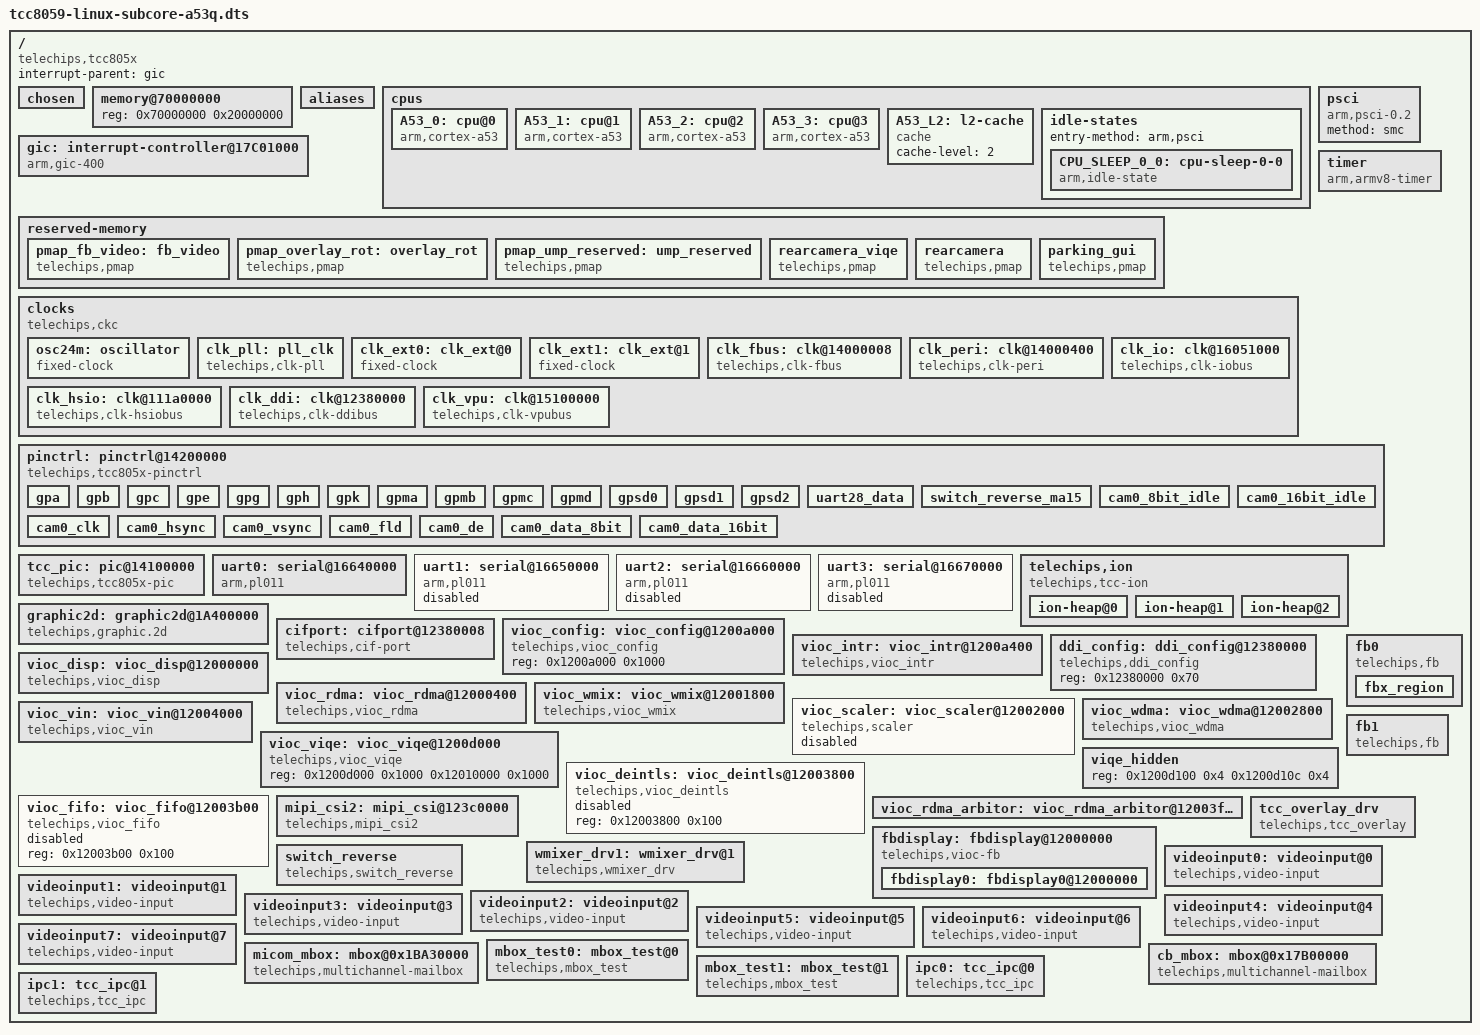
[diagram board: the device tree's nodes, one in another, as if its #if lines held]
// SPDX-License-Identifier: (GPL-2.0-or-later OR MIT)
/*
 * Copyright (C) Telechips Inc.
 * Device tree for Telechips TCC8059 Linux Subcore platform
 */

/dts-v1/;

#include <dt-bindings/interrupt-controller/arm-gic.h>
#include <dt-bindings/clock/telechips,tcc805x-clks.h>
#include <dt-bindings/reset/telechips,tcc805x-reset.h>
#include <dt-bindings/display/tcc805x-vioc.h>
#include <dt-bindings/power/telechips,boot-mode.h>
#include <dt-bindings/gpio/gpio.h>
#include <dt-bindings/mailbox/tcc805x_multi_mailbox/tcc_mbox_ch.h>
#include <dt-bindings/input/input.h>

#include "tcc-pmap-805x-subcore-a53q.dtsi"

/ {
	compatible = "telechips,tcc805x";
	interrupt-parent = <&gic>;
	#address-cells = <1>;
	#size-cells = <1>;

	chosen {
		bootargs = "vmalloc=480M cgroup_disable=memory console=ttyAMA0,115200n8 quiet";
		stdout-path = &uart0;
	};

	memory@70000000 {
		#address-cells = <1>;
		#size-cells = <1>;
		device_type = "memory";
		reg = <0x70000000 0x20000000>;
	};

	aliases {
		serial0 = &uart0;
		videoinput0 = &videoinput0;
		videoinput1 = &videoinput1;
		videoinput2 = &videoinput2;
		videoinput3 = &videoinput3;
		videoinput4 = &videoinput4;
		videoinput5 = &videoinput5;
		videoinput6 = &videoinput6;
		videoinput7 = &videoinput7;
		wmixer-drv1 = &wmixer_drv1;
//		tcc-overlay-drv1 = &tcc_overlay_drv1;
	};

	cpus {
		#address-cells = <1>;
		#size-cells = <0>;

		A53_0: cpu@0 {
			device_type = "cpu";
			compatible = "arm,cortex-a53";
			reg = <0x0>;
			enable-method = "psci";
			next-level-cache = <&A53_L2>;
			cpu-idle-states = <&CPU_SLEEP_0_0>;
			operating-points = <
				/* kHz    uV */
				/*1302000 1200000*/
				/*1226000 1150000*/
				/*1150000 1100000*/
				/*1074000 1050000*/
				/*998000 1100000*/
				/*908000 1100000*/
				950000 900000
			>;

			clocks = <&clk_fbus FBUS_CPU1>;
			clock-names = "cpu0";
			clock-latency = <300000>;
		};

		A53_1: cpu@1 {
			device_type = "cpu";
			compatible = "arm,cortex-a53";
			reg = <0x1>;
			enable-method = "psci";
			next-level-cache = <&A53_L2>;
		};

		A53_2: cpu@2 {
			device_type = "cpu";
			compatible = "arm,cortex-a53";
			reg = <0x2>;
			enable-method = "psci";
			next-level-cache = <&A53_L2>;
		};

		A53_3: cpu@3 {
			device_type = "cpu";
			compatible = "arm,cortex-a53";
			reg = <0x3>;
			enable-method = "psci";
			next-level-cache = <&A53_L2>;
		};

		A53_L2: l2-cache {
			compatible = "cache";
			cache-level = <2>;
		};

		idle-states {
			entry-method = "arm,psci";

			CPU_SLEEP_0_0: cpu-sleep-0-0 {
				compatible = "arm,idle-state";
				local-timer-stop;
				arm,psci-suspend-param = <0x0010000>;
				entry-latency-us = <250>;
				exit-latency-us = <500>;
				min-residency-us = <950>;
			};
		};
	};

	gic: interrupt-controller@17C01000 {
		compatible = "arm,gic-400", "telechips,tcc805x-pic";
		#interrupt-cells = <3>;
		#address-cells = <0>;
		interrupt-controller;
		reg = <0x17C01000 0x1000>,
		      <0x17C02000 0x1000>,
		      <0x17C04000 0x2000>,
		      <0x17C06000 0x2000>;
	};

	psci {
		compatible = "arm,psci-0.2";
		method = "smc";
	};

	timer {
		compatible = "arm,armv8-timer";
		interrupts = <GIC_PPI 13 (GIC_CPU_MASK_SIMPLE(4) | IRQ_TYPE_LEVEL_LOW)>,
			     <GIC_PPI 14 (GIC_CPU_MASK_SIMPLE(4) | IRQ_TYPE_LEVEL_LOW)>,
			     <GIC_PPI 11 (GIC_CPU_MASK_SIMPLE(4) | IRQ_TYPE_LEVEL_LOW)>,
			     <GIC_PPI 10 (GIC_CPU_MASK_SIMPLE(4) | IRQ_TYPE_LEVEL_LOW)>;
	};

	reserved-memory {
		#address-cells = <1>;
		#size-cells = <1>;
		ranges;

		/*-----------------------------------------------------------
		 * Secure Area 1 (CPU R/W, VPU X, GPU R/W, VIOC R)
		 *-----------------------------------------------------------
		 */
		pmap_fb_video: fb_video {
			compatible = "telechips,pmap";
			telechips,pmap-name = "fb_video";
			alloc-ranges = <RESERVED_MEM_BASE RESERVED_MEM_SIZE>;
			size = <PMAP_SIZE_FB_VIDEO>;
			no-map;
		};

		pmap_overlay_rot: overlay_rot {
			compatible = "telechips,pmap";
			telechips,pmap-name = "overlay_rot";
			alloc-ranges = <RESERVED_MEM_BASE RESERVED_MEM_SIZE>;
			size = <PMAP_SIZE_OVERLAY_ROT>; // Max-Displayed-Output(w*h*2) for device-rotation.
			no-map;
		};

		/*-----------------------------------------------------------
		 * Secure Area 4 (CPU X, VPU X, GPU R/W, VIOC R/W)
		 *-----------------------------------------------------------
		 */
		pmap_ump_reserved: ump_reserved {
			compatible = "telechips,pmap";
			telechips,pmap-name = "ump_reserved";
			alloc-ranges = <RESERVED_MEM_BASE RESERVED_MEM_SIZE>;
			size = <PMAP_SIZE_UMP_RESERVED>; // Max-Video-Resolution(Aligned_256KB(w*h*3/2)) * 12 + 1MB
		};

		/*-----------------------------------------------------------
		 * RearCamera Memory (synchronized with bootloader)
		 *-----------------------------------------------------------
		 */
		rearcamera_viqe: rearcamera_viqe {
			compatible = "telechips,pmap";
			telechips,pmap-name = "rearcamera_viqe";
			alloc-ranges = <REARCAMERA_MEM_BASE REARCAMERA_MEM_SIZE>;
			size = <PMAP_SIZE_REARCAMERA_VIQE>;
			no-map;
		};

		rearcamera: rearcamera {
			compatible = "telechips,pmap";
			telechips,pmap-name = "rearcamera";
			alloc-ranges = <REARCAMERA_MEM_BASE REARCAMERA_MEM_SIZE>;
			size = <PMAP_SIZE_REARCAMERA>;
			no-map;
		};

		parking_gui: parking_gui {
			compatible = "telechips,pmap";
			telechips,pmap-name = "parking_gui";
			alloc-ranges = <REARCAMERA_MEM_BASE REARCAMERA_MEM_SIZE>;
			size = <PMAP_SIZE_PARKING_GUI>;
			no-map;
		};
	};

	clocks {
		compatible = "telechips,ckc";

		osc24m: oscillator {
			compatible = "fixed-clock";
			#clock-cells = <0>;
			clock-frequency = <24000000>;
			clock-output-names = "osc24m";
		};

		clk_pll: pll_clk {
			compatible = "telechips,clk-pll";
			#clock-cells = <1>;
			clocks = <&osc24m>;
			clock-output-names = "pll0", "pll1", "pll2", "pll3",
					     "pll4";
		};

		clk_ext0: clk_ext@0 {
			compatible = "fixed-clock";
			#clock-cells = <0>;
			clock-frequency = <24000000>;
			clock-output-names = "clk_ext0";
		};

		clk_ext1: clk_ext@1 {
			compatible = "fixed-clock";
			#clock-cells = <0>;
			clock-frequency = <24000000>;
			clock-output-names = "clk_ext1";
		};

		clk_fbus: clk@14000008 {
			compatible = "telechips,clk-fbus";
			#clock-cells = <1>;
			clock-indices =
				<FBUS_CPU0>, <FBUS_CPU1>, <FBUS_CBUS>, <FBUS_CMBUS>,
				<FBUS_HSIO>, <FBUS_SMU>, <FBUS_GPU>, <FBUS_DDI>,
				<FBUS_G2D>, <FBUS_IO>, <FBUS_HSM>, <FBUS_PCIe0>,
				<FBUS_PCIe1>, <FBUS_VBUS>, <FBUS_CODA>, <FBUS_CHEVCDEC>,
				<FBUS_BHEVCDEC>, <FBUS_CHEVCENC>, <FBUS_BHEVCENC>, <FBUS_MEM>,
				<FBUS_MEM_SUB>, <FBUS_MEM_PHY_USER>,
				<FBUS_MEM_PHY_PERI>;
			clock-output-names =
				"fbus_cpu0", "fbus_cpu1", "fbus_cbus", "fbus_cmbus",
				"fbus_hsio", "fbus_smu", "fbus_gpu", "fbus_ddi",
				"fbus_g2d", "fbus_io", "fbus_hsm", "fbus_pcie0",
				"fbus_pcie1", "fbus_vbus", "fbus_coda", "fbus_chevcdec",
				"fbus_bhevcdec", "fbus_chevcenc", "fbus_bhevcenc", "fbus_mem",
				"fbus_mem_sub", "fbus_mem_phy_user",
				"fbus_mem_phy_peri";
			telechips,clock-flags =
				<0>,    /* FBUS_CPU0 */
				<CLK_IGNORE_UNUSED>,    /* FBUS_CPU1 */
				<(CLK_SET_RATE_GATE | CLK_IGNORE_UNUSED)>,    /* FBUS_CBUS */
				<(CLK_SET_RATE_GATE | CLK_IGNORE_UNUSED)>,    /* FBUS_CMBUS */
				<(CLK_SET_RATE_GATE | CLK_IGNORE_UNUSED)>,    /* FBUS_HSIO */
				<(CLK_SET_RATE_GATE | CLK_IGNORE_UNUSED)>,    /* FBUS_SMU */
				<(CLK_SET_RATE_GATE | CLK_IGNORE_UNUSED)>,   /* FBUS_GPU */
				<(CLK_SET_RATE_GATE | CLK_IGNORE_UNUSED)>,    /* FBUS_DDI */
				<(CLK_SET_RATE_GATE | CLK_IGNORE_UNUSED)>,    /* FBUS_G2D */
				<(CLK_SET_RATE_GATE | CLK_IS_CRITICAL)>,    /* FBUS_IO */
				<(CLK_SET_RATE_GATE | CLK_IGNORE_UNUSED)>,    /* FBUS_HSM */
				<(CLK_SET_RATE_GATE | CLK_IGNORE_UNUSED)>,    /* FBUS_PCIe0 */
				<(CLK_SET_RATE_GATE | CLK_IGNORE_UNUSED)>,    /* FBUS_PCIe1 */
				<(CLK_SET_RATE_GATE | CLK_IGNORE_UNUSED)>,    /* FBUS_VBUS */
				<(CLK_SET_RATE_GATE | CLK_IGNORE_UNUSED)>,    /* FBUS_CODA */
				<(CLK_SET_RATE_GATE | CLK_IGNORE_UNUSED)>,    /* FBUS_CHEVCDEC */
				<(CLK_SET_RATE_GATE | CLK_IGNORE_UNUSED)>,    /* FBUS_BHEVCDEC */
				<(CLK_SET_RATE_GATE | CLK_IGNORE_UNUSED)>,    /* FBUS_CHEVCENC */
				<(CLK_SET_RATE_GATE | CLK_IGNORE_UNUSED)>,    /* FBUS_BHEVCENC */
				<(CLK_SET_RATE_GATE | CLK_IGNORE_UNUSED)>,    /* FBUS_MEM */
				<(CLK_SET_RATE_GATE | CLK_IGNORE_UNUSED)>,    /* FBUS_MEM_SUB */
				<(CLK_SET_RATE_GATE | CLK_IGNORE_UNUSED)>,    /* FBUS_MEM_PHY_USER */
				<(CLK_SET_RATE_GATE | CLK_IGNORE_UNUSED)>;    /* FBUS_MEM_PHY_PERI */
		};

		clk_peri: clk@14000400 {
			compatible = "telechips,clk-peri";
			#clock-cells = <1>;
			clock-indices =
				<PERI_TCX>, <PERI_TCT>, <PERI_TCZ>,
				<PERI_LCDTIMER>, <PERI_LCD0>, <PERI_LCD1>,
				<PERI_LCD2>, <PERI_CPUINTERFACE0>,
				<PERI_CPUINTERFACE1>, <PERI_LCD3>, <PERI_GMAC>,
				<PERI_GMAC_PTP>, <PERI_PCIE0_AUX>,
				<PERI_PCIE0_REF_EXT>, <PERI_PCIE0_PHY_CR_CLK>,
				<PERI_PCIE1_AUX>, <PERI_PCIE1_REF_EXT>,
				<PERI_PCIE1_PHY_CR_CLK>, <PERI_RMT>, <PERI_GPSB3>,
				<PERI_SDMMC1>, <PERI_SDMMC2>, <PERI_CEC1_CORE>,
				<PERI_MDAI0>, <PERI_MFLT0_DAI>, <PERI_MSPDIF0>,
				<PERI_SRCH0_CORE>, <PERI_SRCH0_FILTER>,
				<PERI_SRCH0_SPDIF>, <PERI_PDM>, <PERI_CEC1_SFR>,
				<PERI_TSADC>, <PERI_I2C0>, <PERI_I2C1>, <PERI_I2C2>,
				<PERI_I2C3>, <PERI_UART0>, <PERI_UART1>,
				<PERI_UART2>, <PERI_UART3>, <PERI_MDAI1>,
				<PERI_MFLT1_DAI>, <PERI_MSPDIF1>, <PERI_MDAI2>,
				<PERI_GPSB0>, <PERI_GPSB1>, <PERI_GPSB2>,
				<PERI_GPSBMS0>, <PERI_GPSBMS1>, <PERI_GPSBMS2>,
				<PERI_UART4>, <PERI_AUX0_INPUT>,
				<PERI_AUX1_INPUT>, <PERI_MFLT2_DAI>,
				<PERI_AUX0_OUTPUT>, <PERI_AUX1_OUTPUT>,
				<PERI_MSPDIF2>, <PERI_IC_TC>, <PERI_SRCH1_CORE>,
				<PERI_SRCH1_FILTER>, <PERI_SRCH1_SPDIF>,
				<PERI_SRCH2_CORE>, <PERI_SRCH2_FILTER>,
				<PERI_SRCH2_SPDIF>, <PERI_SRCH3_CORE>,
				<PERI_SRCH3_FILTER>, <PERI_SRCH3_SPDIF>,
				<PERI_UART5>, <PERI_UART6>, <PERI_UART7>,
				<PERI_UART8>, <PERI_MDAI3>, <PERI_MFLT3_DAI>,
				<PERI_MSPDIF3>, <PERI_TSRX0>, <PERI_TSRX1>,
				<PERI_TSRX2>, <PERI_TSRX3>, <PERI_TSRX4>,
				<PERI_TSRX5>, <PERI_TSRX6>, <PERI_TSRX7>,
				<PERI_TSRX8>, <PERI_CB_WDT>, <PERI_OUT0>,
				<PERI_OUT1>, <PERI_OUT2>, <PERI_OUT3>, <PERI_OUT4>,
				<PERI_OUT5>, <PERI_HSMB>;

				clock-output-names =
				"peri_tcx", "peri_tct", "peri_tcz",
				"peri_lcdtimer", "peri_lcd0", "peri_lcd1",
				"peri_lcd2", "peri_cpuinterface0",
				"peri_cpuinterface1", "peri_lcd3", "peri_gmac",
				"peri_gmac_ptp", "peri_pcie0_aux",
				"peri_pcie0_ref_ext", "peri_pcie0_phy_cr_clk",
				"peri_pcie1_aux", "peri_pcie1_ref_ext",
				"peri_pcie1_phy_cr_clk", "peri_rmt", "peri_gpsb3",
				"peri_sdmmc1", "peri_sdmmc2", "peri_cec1_core",
				"peri_mdai0", "peri_mflt0_dai", "peri_mspdif0",
				"peri_srch0_core", "peri_srch0_filter",
				"peri_srch0_spdif", "peri_pdm", "peri_cec1_sfr",
				"peri_tsadc", "peri_i2c0", "peri_i2c1", "peri_i2c2",
				"peri_i2c3", "peri_uart0", "peri_uart1",
				"peri_uart2", "peri_uart3", "peri_mdai1",
				"peri_mflt1_dai", "peri_mspdif1", "peri_mdai2",
				"peri_gpsb0", "peri_gpsb1", "peri_gpsb2",
				"peri_gpsbms0", "peri_gpsbms1", "peri_gpsbms2",
				"peri_uart4", "peri_aux0_input",
				"peri_aux1_input", "peri_mflt2_dai",
				"peri_aux0_output", "peri_aux1_output",
				"peri_mspdif2", "peri_ic_tc", "peri_srch1_core",
				"peri_srch1_filter", "peri_srch1_spdif",
				"peri_srch2_core", "peri_srch2_filter",
				"peri_srch2_spdif", "peri_srch3_core",
				"peri_srch3_filter", "peri_srch3_spdif",
				"peri_uart5", "peri_uart6", "peri_uart7",
				"peri_uart8", "peri_mdai3", "peri_mflt3_dai",
				"peri_mspdif3", "peri_tsrx0", "peri_tsrx1",
				"peri_tsrx2", "peri_tsrx3", "peri_tsrx4",
				"peri_tsrx5", "peri_tsrx6", "peri_tsrx7",
				"peri_tsrx8", "peri_cb_wdt", "peri_out0",
				"peri_out1", "peri_out2", "peri_out3", "peri_out4",
				"peri_out5", "peri_hsmb";
			telechips,clock-flags =
				<CLK_IGNORE_UNUSED>,    /* PERI_TCX */
				<CLK_IGNORE_UNUSED>,    /* PERI_TCT */
				<CLK_IGNORE_UNUSED>,    /* PERI_TCZ */
				<CLK_IGNORE_UNUSED>,    /* PERI_LCDTIMER */
				<CLK_IGNORE_UNUSED>,    /* PERI_LCD0 */
				<CLK_IGNORE_UNUSED>,    /* PERI_LCD1 */
				<CLK_IGNORE_UNUSED>,    /* PERI_LCD2 */
				<CLK_IGNORE_UNUSED>,    /* PERI_CPUINTERFACE0 */
				<CLK_IGNORE_UNUSED>,    /* PERI_CPUINTERFACE1 */
				<CLK_IGNORE_UNUSED>,    /* PERI_LCD3 */
				<CLK_IGNORE_UNUSED>,    /* PERI_GMAC */
				<CLK_IGNORE_UNUSED>,    /* PERI_GMAC_PTP */
				<CLK_IGNORE_UNUSED>,    /* PERI_PCIE0_AUX */
				<CLK_IGNORE_UNUSED>,    /* PERI_PCIE0_REF_EXT */
				<CLK_IGNORE_UNUSED>,    /* PERI_PCIE0_PHY_CR_CLK */
				<CLK_IGNORE_UNUSED>,    /* PERI_PCIE1_AUX */
				<CLK_IGNORE_UNUSED>,    /* PERI_PCIE1_REF_EXT */
				<CLK_IGNORE_UNUSED>,    /* PERI_PCIE1_PHY_CR_CLK */
				<CLK_IGNORE_UNUSED>,    /* PERI_RMT */
				<CLK_IGNORE_UNUSED>,    /* PERI_GPSB3 */
				<CLK_IGNORE_UNUSED>,    /* PERI_SDMMC1 */
				<CLK_IGNORE_UNUSED>,    /* PERI_SDMMC2 */
				<CLK_IGNORE_UNUSED>,    /* PERI_CEC1_CORE */
				<CLK_IGNORE_UNUSED>,    /* PERI_MDAI0 */
				<CLK_IGNORE_UNUSED>,    /* PERI_MFLT0_DAI */
				<CLK_IGNORE_UNUSED>,    /* PERI_MSPDIF0 */
				<CLK_IGNORE_UNUSED>,    /* PERI_SRCH0_CORE */
				<CLK_IGNORE_UNUSED>,    /* PERI_SRCH0_FILTER */
				<CLK_IGNORE_UNUSED>,    /* PERI_SRCH0_SPDIF */
				<CLK_IGNORE_UNUSED>,    /* PERI_PDM */
				<CLK_IGNORE_UNUSED>,    /* PERI_CEC1_SFR */
				<CLK_IGNORE_UNUSED>,    /* PERI_TSADC */
				<CLK_IGNORE_UNUSED>,    /* PERI_I2C0 */
				<CLK_IGNORE_UNUSED>,    /* PERI_I2C1 */
				<CLK_IGNORE_UNUSED>,    /* PERI_I2C2 */
				<CLK_IGNORE_UNUSED>,    /* PERI_I2C3 */
				<CLK_IGNORE_UNUSED>,    /* PERI_UART0 */
				<CLK_IGNORE_UNUSED>,    /* PERI_UART1 */
				<CLK_IGNORE_UNUSED>,    /* PERI_UART2 */
				<CLK_IGNORE_UNUSED>,    /* PERI_UART3 */
				<CLK_IGNORE_UNUSED>,    /* PERI_MDAI1 */
				<CLK_IGNORE_UNUSED>,    /* PERI_MFLT1_DAI */
				<CLK_IGNORE_UNUSED>,    /* PERI_MSPDIF1 */
				<CLK_IGNORE_UNUSED>,    /* PERI_MDAI2 */
				<CLK_IGNORE_UNUSED>,    /* PERI_GPSB0 */
				<CLK_IGNORE_UNUSED>,    /* PERI_GPSB1 */
				<CLK_IGNORE_UNUSED>,    /* PERI_GPSB2 */
				<CLK_IGNORE_UNUSED>,    /* PERI_GPSBMS0 */
				<CLK_IGNORE_UNUSED>,    /* PERI_GPSBMS1 */
				<CLK_IGNORE_UNUSED>,    /* PERI_GPSBMS2 */
				<CLK_IGNORE_UNUSED>,    /* PERI_UART4 */
				<CLK_IGNORE_UNUSED>,    /* PERI_AUX0_INPUT */
				<CLK_IGNORE_UNUSED>,    /* PERI_AUX1_INPUT */
				<CLK_IGNORE_UNUSED>,    /* PERI_MFLT2_DAI */
				<CLK_IGNORE_UNUSED>,    /* PERI_AUX0_OUTPUT */
				<CLK_IGNORE_UNUSED>,    /* PERI_AUX1_OUTPUT */
				<CLK_IGNORE_UNUSED>,    /* PERI_MSPDIF2 */
				<CLK_IGNORE_UNUSED>,    /* PERI_IC_TC */
				<CLK_IGNORE_UNUSED>,    /* PERI_SRCH1_CORE */
				<CLK_IGNORE_UNUSED>,    /* PERI_SRCH1_FILTER */
				<CLK_IGNORE_UNUSED>,    /* PERI_SRCH1_SPDIF */
				<CLK_IGNORE_UNUSED>,    /* PERI_SRCH2_CORE */
				<CLK_IGNORE_UNUSED>,    /* PERI_SRCH2_FILTER */
				<CLK_IGNORE_UNUSED>,    /* PERI_SRCH2_SPDIF */
				<CLK_IGNORE_UNUSED>,    /* PERI_SRCH3_CORE */
				<CLK_IGNORE_UNUSED>,    /* PERI_SRCH3_FILTER */
				<CLK_IGNORE_UNUSED>,    /* PERI_SRCH3_SPDIF */
				<CLK_IGNORE_UNUSED>,    /* PERI_UART5 */
				<CLK_IGNORE_UNUSED>,    /* PERI_UART6 */
				<CLK_IGNORE_UNUSED>,    /* PERI_UART7 */
				<CLK_IGNORE_UNUSED>,    /* PERI_UART8 */
				<CLK_IGNORE_UNUSED>,    /* PERI_MDAI3 */
				<CLK_IGNORE_UNUSED>,    /* PERI_MFLT3_DAI */
				<CLK_IGNORE_UNUSED>,    /* PERI_MSPDIF3 */
				<CLK_IGNORE_UNUSED>,    /* PERI_TSRX0 */
				<CLK_IGNORE_UNUSED>,    /* PERI_TSRX1 */
				<CLK_IGNORE_UNUSED>,    /* PERI_TSRX2 */
				<CLK_IGNORE_UNUSED>,    /* PERI_TSRX3 */
				<CLK_IGNORE_UNUSED>,    /* PERI_TSRX4 */
				<CLK_IGNORE_UNUSED>,    /* PERI_TSRX5 */
				<CLK_IGNORE_UNUSED>,    /* PERI_TSRX6 */
				<CLK_IGNORE_UNUSED>,    /* PERI_TSRX7 */
				<CLK_IGNORE_UNUSED>,    /* PERI_TSRX8 */
				<CLK_IGNORE_UNUSED>,    /* PERI_CB_WDT */
				<CLK_IGNORE_UNUSED>,    /* PERI_OUT0 */
				<CLK_IGNORE_UNUSED>,    /* PERI_OUT1 */
				<CLK_IGNORE_UNUSED>,    /* PERI_OUT2 */
				<CLK_IGNORE_UNUSED>,    /* PERI_OUT3 */
				<CLK_IGNORE_UNUSED>,    /* PERI_OUT4 */
				<CLK_IGNORE_UNUSED>,    /* PERI_OUT5 */
				<CLK_IGNORE_UNUSED>;    /* PERI_HSMB */
		};

		clk_io: clk@16051000 {
			compatible = "telechips,clk-iobus";
			#clock-cells = <1>;
			clocks = <&clk_fbus FBUS_IO>;
			clock-indices =
				<IOBUS_IC_TC>, <IOBUS_GPSB6>, <IOBUS_PL080>,
                                <IOBUS_ASRC>, <IOBUS_DMA0>, <IOBUS_DMA1>,
                                <IOBUS_DMA2>, <IOBUS_DMA>, <IOBUS_PWM>,
                                <IOBUS_I2C_S2>, <IOBUS_REMOCON>, <IOBUS_PRT>,
                                <IOBUS_ADMA0>, <IOBUS_DAI0>, <IOBUS_SPDIF0>,
                                <IOBUS_AUDIO0>, <IOBUS_ADMA3>, <IOBUS_DAI3>,
                                <IOBUS_SPDIF3>, <IOBUS_AUDIO3>, <IOBUS_I2C_M0>,
                                <IOBUS_I2C_M1>, <IOBUS_I2C_M2>, <IOBUS_I2C_M3>,
                                <IOBUS_I2C_S0>, <IOBUS_I2C_S1>, <IOBUS_I2C0>,
                                <IOBUS_I2C1>, <IOBUS_GPSB_2>, <IOBUS_GPSB0>,
                                <IOBUS_GPSB1>, <IOBUS_GPSB2>, <IOBUS_GPSB3>,
                                <IOBUS_GPSB4>, <IOBUS_GPSB5>, <IOBUS_GPSB>,
                                <IOBUS_I2C_S3>, <IOBUS_I2C_M4>, <IOBUS_I2C_M5>,
                                <IOBUS_I2C_M6>, <IOBUS_I2C_M7>, <IOBUS_UART0>,
                                <IOBUS_UART1>, <IOBUS_UART2>, <IOBUS_UART3>,
                                <IOBUS_UART4>, <IOBUS_UART5>, <IOBUS_UART6>,
                                <IOBUS_UART7>, <IOBUS_UART8>, <IOBUS_SMARTCARD4>,
                                <IOBUS_UDMA0>, <IOBUS_UDMA1>, <IOBUS_UDMA2>,
                                <IOBUS_UDMA3>, <IOBUS_UART_SMARTCARD0>,
                                <IOBUS_UART_SMARTCARD1>, <IOBUS_UDMA4>, <IOBUS_UDMA5>,
                                <IOBUS_UDMA6>, <IOBUS_UDMA7>, <IOBUS_UDMA8>,
                                <IOBUS_ADMA1>, <IOBUS_DAI1>, <IOBUS_SPDIF1>,
                                <IOBUS_AUDIO1>, <IOBUS_ADMA2>, <IOBUS_DAI2>,
                                <IOBUS_SPDIF2>, <IOBUS_AUDIO2>, <IOBUS_ADMA4>,
                                <IOBUS_DAI4>, <IOBUS_SPDIF4>, <IOBUS_AUDIO4>,
                                <IOBUS_ADMA5>, <IOBUS_DAI5>, <IOBUS_SPDIF5>,
                                <IOBUS_AUDIO5>, <IOBUS_ADMA6>, <IOBUS_DAI6>,
                                <IOBUS_SPDIF6>, <IOBUS_AUDIO6>, <IOBUS_ADMA7>,
                                <IOBUS_DAI7>, <IOBUS_AUDIO7>, <IOBUS_GDMA1>,
                                <IOBUS_SDMMC1>, <IOBUS_SDMMC2>, <IOBUS_SDMMC>,
                                <IOBUS_SMC>, <IOBUS_NFC>, <IOBUS_EDICFG>,
                                <IOBUS_EDI>, <IOBUS_RTC>;
			clock-output-names =
				"iobus_ic_tc", "iobus_gpsb6", "iobus_pl080",
                                "iobus_asrc", "iobus_dma0", "iobus_dma1",
                                "iobus_dma2", "iobus_dma", "iobus_pwm",
                                "iobus_i2c_s2", "iobus_remocon", "iobus_prt",
                                "iobus_adma0", "iobus_dai0", "iobus_spdif0",
                                "iobus_audio0", "iobus_adma3", "iobus_dai3",
                                "iobus_spdif3", "iobus_audio3", "iobus_i2c_m0",
                                "iobus_i2c_m1", "iobus_i2c_m2", "iobus_i2c_m3",
                                "iobus_i2c_s0", "iobus_i2c_s1", "iobus_i2c0",
                                "iobus_i2c1", "iobus_gpsb_2", "iobus_gpsb0",
                                "iobus_gpsb1", "iobus_gpsb2", "iobus_gpsb3",
                                "iobus_gpsb4", "iobus_gpsb5", "iobus_gpsb",
                                "iobus_i2c_s3", "iobus_i2c_m4", "iobus_i2c_m5",
                                "iobus_i2c_m6", "iobus_i2c_m7", "iobus_uart0",
                                "iobus_uart1", "iobus_uart2", "iobus_uart3",
                                "iobus_uart4", "iobus_uart5", "iobus_uart6",
                                "iobus_uart7", "iobus_uart8", "iobus_smartcard4",
                                "iobus_udma0", "iobus_udma1", "iobus_udma2",
                                "iobus_udma3", "iobus_uart_smartcard0",
                                "iobus_uart_smartcard1", "iobus_udma4", "iobus_udma5",
                                "iobus_udma6", "iobus_udma7", "iobus_udma8",
                                "iobus_adma1", "iobus_dai1", "iobus_spdif1",
                                "iobus_audio1", "iobus_adma2", "iobus_dai2",
                                "iobus_spdif2", "iobus_audio2", "iobus_adma4",
                                "iobus_dai4", "iobus_spdif4", "iobus_audio4",
                                "iobus_adma5", "iobus_dai5", "iobus_spdif5",
                                "iobus_audio5", "iobus_adma6", "iobus_dai6",
                                "iobus_spdif6", "iobus_audio6", "iobus_adma7",
                                "iobus_dai7", "iobus_audio7", "iobus_gdma1",
                                "iobus_sdmmc1", "iobus_sdmmc2", "iobus_sdmmc",
                                "iobus_smc", "iobus_nfc", "iobus_edicfg",
                                "iobus_edi", "iobus_rtc";
			telechips,clock-flags =
				<CLK_IGNORE_UNUSED>,    /* IOBUS_IC_TC */
                                <CLK_IGNORE_UNUSED>,    /* IOBUS_GPSB6 */
                                <CLK_IGNORE_UNUSED>,    /* IOBUS_PL080 */
                                <CLK_IGNORE_UNUSED>,    /* IOBUS_ASRC */
                                <CLK_IGNORE_UNUSED>,    /* IOBUS_DMA0 */
                                <CLK_IGNORE_UNUSED>,    /* IOBUS_DMA1 */
                                <CLK_IGNORE_UNUSED>,    /* IOBUS_DMA2 */
                                <CLK_IGNORE_UNUSED>,    /* IOBUS_DMA */
                                <CLK_IGNORE_UNUSED>,    /* IOBUS_PWM */
                                <CLK_IGNORE_UNUSED>,    /* IOBUS_I2C_S2 */
                                <CLK_IGNORE_UNUSED>,    /* IOBUS_REMOCON */
                                <CLK_IGNORE_UNUSED>,    /* IOBUS_PRT */
                                <CLK_IGNORE_UNUSED>,    /* IOBUS_ADMA0 */
                                <CLK_IGNORE_UNUSED>,    /* IOBUS_DAI0 */
                                <CLK_IGNORE_UNUSED>,    /* IOBUS_SPDIF0 */
                                <CLK_IGNORE_UNUSED>,    /* IOBUS_AUDIO0 */
                                <CLK_IGNORE_UNUSED>,    /* IOBUS_ADMA3 */
                                <CLK_IGNORE_UNUSED>,    /* IOBUS_DAI3 */
                                <CLK_IGNORE_UNUSED>,    /* IOBUS_SPDIF3 */
                                <CLK_IGNORE_UNUSED>,    /* IOBUS_AUDIO3 */
                                <CLK_IGNORE_UNUSED>,    /* IOBUS_I2C_M0 */
                                <CLK_IGNORE_UNUSED>,    /* IOBUS_I2C_M1 */
                                <CLK_IGNORE_UNUSED>,    /* IOBUS_I2C_M2 */
                                <CLK_IGNORE_UNUSED>,    /* IOBUS_I2C_M3 */
                                <CLK_IGNORE_UNUSED>,    /* IOBUS_I2C_S0 */
                                <CLK_IGNORE_UNUSED>,    /* IOBUS_I2C_S1 */
                                <CLK_IGNORE_UNUSED>,    /* IOBUS_I2C0 */
                                <CLK_IGNORE_UNUSED>,    /* IOBUS_I2C1 */
                                <CLK_IGNORE_UNUSED>,    /* IOBUS_GPSB_2 */
                                <CLK_IGNORE_UNUSED>,    /* IOBUS_GPSB0 */
                                <CLK_IGNORE_UNUSED>,    /* IOBUS_GPSB1 */
                                <CLK_IGNORE_UNUSED>,    /* IOBUS_GPSB2 */
                                <CLK_IGNORE_UNUSED>,    /* IOBUS_GPSB3 */
                                <CLK_IGNORE_UNUSED>,    /* IOBUS_GPSB4 */
                                <CLK_IGNORE_UNUSED>,    /* IOBUS_GPSB5 */
                                <CLK_IGNORE_UNUSED>,    /* IOBUS_GPSB */
                                <CLK_IGNORE_UNUSED>,    /* IOBUS_I2C_S3 */
                                <CLK_IGNORE_UNUSED>,    /* IOBUS_I2C_M4 */
                                <CLK_IGNORE_UNUSED>,    /* IOBUS_I2C_M5 */
                                <CLK_IGNORE_UNUSED>,    /* IOBUS_I2C_M6 */
                                <CLK_IGNORE_UNUSED>,    /* IOBUS_I2C_M7 */
                                <CLK_IGNORE_UNUSED>,    /* IOBUS_UART0 */
                                <CLK_IGNORE_UNUSED>,    /* IOBUS_UART1 */
                                <CLK_IGNORE_UNUSED>,    /* IOBUS_UART2 */
                                <CLK_IGNORE_UNUSED>,    /* IOBUS_UART3 */
                                <CLK_IGNORE_UNUSED>,    /* IOBUS_UART4 */
                                <CLK_IGNORE_UNUSED>,    /* IOBUS_UART5 */
                                <CLK_IGNORE_UNUSED>,    /* IOBUS_UART6 */
                                <CLK_IGNORE_UNUSED>,    /* IOBUS_UART7 */
                                <CLK_IGNORE_UNUSED>,    /* IOBUS_UART8 */
                                <CLK_IGNORE_UNUSED>,    /* IOBUS_SMARTCARD4 */
                                <CLK_IGNORE_UNUSED>,    /* IOBUS_UDMA0 */
                                <CLK_IGNORE_UNUSED>,    /* IOBUS_UDMA1 */
                                <CLK_IGNORE_UNUSED>,    /* IOBUS_UDMA2 */
                                <CLK_IGNORE_UNUSED>,    /* IOBUS_UDMA3 */
                                <CLK_IGNORE_UNUSED>,    /* IOBUS_UART_SMARTCARD0 */
                                <CLK_IGNORE_UNUSED>,    /* IOBUS_UART_SMARTCARD1 */
                                <CLK_IGNORE_UNUSED>,    /* IOBUS_UDMA4 */
                                <CLK_IGNORE_UNUSED>,    /* IOBUS_UDMA5 */
				<CLK_IGNORE_UNUSED>,    /* IOBUS_UDMA6 */
                                <CLK_IGNORE_UNUSED>,    /* IOBUS_UDMA7 */
                                <CLK_IGNORE_UNUSED>,    /* IOBUS_UDMA8 */
                                <CLK_IGNORE_UNUSED>,    /* IOBUS_ADMA1 */
                                <CLK_IGNORE_UNUSED>,    /* IOBUS_DAI1 */
                                <CLK_IGNORE_UNUSED>,    /* IOBUS_SPDIF1 */
                                <CLK_IGNORE_UNUSED>,    /* IOBUS_AUDIO1 */
                                <CLK_IGNORE_UNUSED>,    /* IOBUS_ADMA2 */
                                <CLK_IGNORE_UNUSED>,    /* IOBUS_DAI2 */
                                <CLK_IGNORE_UNUSED>,    /* IOBUS_SPDIF2 */
                                <CLK_IGNORE_UNUSED>,    /* IOBUS_AUDIO2 */
                                <CLK_IGNORE_UNUSED>,    /* IOBUS_ADMA4 */
                                <CLK_IGNORE_UNUSED>,    /* IOBUS_DAI4 */
                                <CLK_IGNORE_UNUSED>,    /* IOBUS_SPDIF4 */
                                <CLK_IGNORE_UNUSED>,    /* IOBUS_AUDIO4 */
                                <CLK_IGNORE_UNUSED>,    /* IOBUS_ADMA5 */
                                <CLK_IGNORE_UNUSED>,    /* IOBUS_DAI5 */
                                <CLK_IGNORE_UNUSED>,    /* IOBUS_SPDIF5 */
                                <CLK_IGNORE_UNUSED>,    /* IOBUS_AUDIO5 */
                                <CLK_IGNORE_UNUSED>,    /* IOBUS_ADMA6 */
                                <CLK_IGNORE_UNUSED>,    /* IOBUS_DAI6 */
                                <CLK_IGNORE_UNUSED>,    /* IOBUS_SPDIF6 */
                                <CLK_IGNORE_UNUSED>,    /* IOBUS_AUDIO6 */
                                <CLK_IGNORE_UNUSED>,    /* IOBUS_ADMA7 */
                                <CLK_IGNORE_UNUSED>,    /* IOBUS_DAI7 */
                                <CLK_IGNORE_UNUSED>,    /* IOBUS_AUDIO7 */
                                <CLK_IGNORE_UNUSED>,    /* IOBUS_GDMA1 */
                                <CLK_IGNORE_UNUSED>,    /* IOBUS_SDMMC1 */
                                <CLK_IGNORE_UNUSED>,    /* IOBUS_SDMMC2 */
                                <CLK_IGNORE_UNUSED>,    /* IOBUS_SDMMC */
                                <CLK_IGNORE_UNUSED>,    /* IOBUS_SMC */
                                <CLK_IGNORE_UNUSED>,    /* IOBUS_NFC */
                                <CLK_IGNORE_UNUSED>,    /* IOBUS_EDICFG */
                                <CLK_IGNORE_UNUSED>,    /* IOBUS_EDI */
                                <CLK_IGNORE_UNUSED>;    /* IOBUS_RTC */
		};

		clk_hsio: clk@111a0000 {
			compatible = "telechips,clk-hsiobus";
			#clock-cells = <1>;
			clocks = <&clk_fbus FBUS_HSIO>;
			clock-indices =
				<HSIOBUS_USB30>, <HSIOBUS_GMAC>,
                                <HSIOBUS_USB20H>, <HSIOBUS_CIPHER>,
                                <HSIOBUS_DWC_OTG>, <HSIOBUS_SECURE_WRAP>,
                                <HSIOBUS_TRNG>;
			clock-output-names =
				"hsiobus_usb30", "hsiobus_gmac",
                                "hsiobus_usb20h", "hsiobus_cipher",
                                "hsiobus_dwc_otg", "hsiobus_secure_wrap",
                                "hsiobus_trng";
			telechips,clock-flags =
				<CLK_IGNORE_UNUSED>,    /* HSIOBUS_USB30 */
                                <CLK_IGNORE_UNUSED>,    /* HSIOBUS_GMAC */
                                <CLK_IGNORE_UNUSED>,    /* HSIOBUS_USB20H */
                                <CLK_IGNORE_UNUSED>,    /* HSIOBUS_CIPHER */
                                <CLK_IGNORE_UNUSED>,    /* HSIOBUS_DWC_OTG */
                                <CLK_IGNORE_UNUSED>,    /* HSIOBUS_SECURE_WRAP */
                                <CLK_IGNORE_UNUSED>;    /* HSIOBUS_TRNG */
		};

		clk_ddi: clk@12380000 {
			compatible = "telechips,clk-ddibus";
			#clock-cells = <1>;
			clocks = <&clk_fbus FBUS_DDI>;
			clock-indices =
				<DDIBUS_VIOC>, <DDIBUS_HDMI>, <DDIBUS_MIPI>,
				<DDIBUS_LVDS>;
			clock-output-names =
				"ddibus_vioc", "ddibus_hdmi", "ddibus_mipi",
				"ddibus_lvds";
			telechips,clock-flags =
				<CLK_IGNORE_UNUSED>,	/* DDIBUS_VIOC */
				<CLK_IGNORE_UNUSED>,	/* DDIBUS_HDMI */
				<CLK_IGNORE_UNUSED>,	/* DDIBUS_MIPI */
				<CLK_IGNORE_UNUSED>;	/* DDIBUS_LVDS */
		};

		clk_vpu: clk@15100000 {
			compatible = "telechips,clk-vpubus";
			#clock-cells = <1>;
			clocks = <&clk_fbus FBUS_VBUS>;
			clock-indices =
				<VIDEOBUS_JPEG>, <VIDEOBUS_CODA_BUS>,
				<VIDEOBUS_CODA_CORE>, <VIDEOBUS_HEVC_BUS>,
				<VIDEOBUS_HEVC_CORE>, <VIDEOBUS_HEVC_ENCODER>;
			clock-output-names =
				"videobus_jpeg", "videobus_coda_bus",
				"videobus_coda_core", "videobus_hevc_bus",
				"videobus_hevc_core", "videobus_hevc_encoder";
			telechips,clock-flags =
				<CLK_IGNORE_UNUSED>,	/* VIDEOBUS_JPEG */
				<CLK_IGNORE_UNUSED>,	/* VIDEOBUS_CODA_BUS */
				<CLK_IGNORE_UNUSED>,	/* VIDEOBUS_CODA_CORE */
				<CLK_IGNORE_UNUSED>,	/* VIDEOBUS_HEVC_BUS */
				<CLK_IGNORE_UNUSED>,	/* VIDEOBUS_HEVC_CORE */
				<CLK_IGNORE_UNUSED>;	/* VIDEOBUS_HEVC_ENCODER */
		};
	};

	pinctrl: pinctrl@14200000 {
		compatible = "telechips,tcc805x-pinctrl";
		reg = <0x14200000 0x7C0 0x1B937000 0xA30>;	/* gpio, pmgpio */
		gpio-controller;
		#address-cells = <1>;
		#size-cells = <0>;
		#gpio-cells = <3>;
		interrupts = <GIC_SPI 0 0>,
			     <GIC_SPI 1 0>,
			     <GIC_SPI 2 0>,
			     <GIC_SPI 3 0>,
			     <GIC_SPI 4 0>,
			     <GIC_SPI 5 0>,
			     <GIC_SPI 6 0>,
			     <GIC_SPI 7 0>,
			     <GIC_SPI 8 0>,
			     <GIC_SPI 9 0>,
			     <GIC_SPI 10 0>,
			     <GIC_SPI 11 0>,
			     <GIC_SPI 12 0>,
			     <GIC_SPI 13 0>,
			     <GIC_SPI 14 0>,
			     <GIC_SPI 15 0>,
			     <GIC_SPI 16 0>,
			     <GIC_SPI 17 0>,
			     <GIC_SPI 18 0>,
			     <GIC_SPI 19 0>,
			     <GIC_SPI 20 0>,
			     <GIC_SPI 21 0>,
			     <GIC_SPI 22 0>,
			     <GIC_SPI 23 0>,
			     <GIC_SPI 24 0>,
			     <GIC_SPI 25 0>,
			     <GIC_SPI 26 0>,
			     <GIC_SPI 27 0>,
			     <GIC_SPI 28 0>,
			     <GIC_SPI 29 0>,
			     <GIC_SPI 30 0>,
			     <GIC_SPI 31 0>;
	};

        tcc_pic: pic@14100000 {
                compatible = "telechips,tcc805x-pic";
                reg = <0x0 0x141000E0 0x0 0x0018>,  /* pol_0_base */
                      <0x0 0x14600100 0x0 0x0024>,  /* pol_1_base */
                      <0x0 0x14800040 0x0 0x003C>,  /* cmb_cm4_base */
                      <0x0 0x14900040 0x0 0x003C>,  /* strgb_cm4_base */
                      <0x0 0x0 0x0 0x0>;            /* ca7_irqo_en_base */
                demarcation = <192>;
                max_irq = <480>;
        };

	uart0: serial@16640000 {
		compatible = "arm,pl011", "arm,primecell";
		reg = <0x16640000 0x1000>;
		arm,primecell-periphid = <0x001feff7>;
		interrupts = <GIC_SPI 69 IRQ_TYPE_LEVEL_HIGH>;
		clocks = <&clk_peri PERI_UART4>, <&clk_io IOBUS_UART4>;
		clock-names = "uartclk", "apb_pclk";
		status = "disabled";
	};

        uart1: serial@16650000 {
                compatible = "arm,pl011", "arm,primecell";
                reg = <0x16650000 0x1000>;
                arm,primecell-periphid = <0x001feff7>;
                interrupts = <GIC_SPI 111 IRQ_TYPE_LEVEL_HIGH>;
                clocks = <&clk_peri PERI_UART5>, <&clk_io IOBUS_UART5>;
                clock-names = "uartclk", "apb_pclk";
                status = "disabled";
        };

        uart2: serial@16660000 {
                compatible = "arm,pl011", "arm,primecell";
                reg = <0x16660000 0x1000>;
                arm,primecell-periphid = <0x001feff7>;
                interrupts = <GIC_SPI 112 IRQ_TYPE_LEVEL_HIGH>;
                clocks = <&clk_peri PERI_UART6>, <&clk_io IOBUS_UART6>;
                clock-names = "uartclk", "apb_pclk";
                status = "disabled";
        };

        uart3: serial@16670000 {
                compatible = "arm,pl011", "arm,primecell";
                reg = <0x16670000 0x1000>;
                arm,primecell-periphid = <0x001feff7>;
                interrupts = <GIC_SPI 113 IRQ_TYPE_LEVEL_HIGH>;
                clocks = <&clk_peri PERI_UART7>, <&clk_io IOBUS_UART7>;
                clock-names = "uartclk", "apb_pclk";
                status = "disabled";
        };

	telechips,ion {
		compatible = "telechips,tcc-ion";
		#address-cells = <1>;
		#size-cells = <0>;

		ion-heap@0 {
			reg = <0>;
			telechips,ion-heap-name = "ion_noncontig_heap";
		};

		ion-heap@1 {
			reg = <1>;
			telechips,ion-heap-name = "ion_contig_heap";
		};

		ion-heap@2 {
			reg = <2>;
			telechips,ion-heap-name = "ion_carveout_heap";
		};
	};

	graphic2d:graphic2d@1A400000 {
		compatible = "telechips,graphic.2d";
		reg = <0x1A400000 0x1000>;
		interrupts = <GIC_SPI 133 IRQ_TYPE_LEVEL_HIGH>;
		clocks =<&clk_fbus FBUS_G2D>;
		status ="okay";
	};

	cifport: cifport@12380008 {
		compatible = "telechips,cif-port";
		reg = <0x12380008 0x4>;
		statue = "okay";
	};

	vioc_config: vioc_config@1200a000 {
		compatible = "telechips,vioc_config";
		reg = <0x1200a000 0x1000>;
	};

	vioc_intr: vioc_intr@1200a400 {
		compatible = "telechips,vioc_intr";
		reg = <0x1200a400 0x100>;
		interrupts = <GIC_SPI VIOC0_IRQI IRQ_TYPE_LEVEL_HIGH>;
	};

	ddi_config: ddi_config@12380000 {
		compatible = "telechips,ddi_config";
		reg = <0x12380000 0x70>;
	};

#if 0 /* This is not in TCC805x */
	output_config: output_config@12100200 {
		compatible = "telechips,output_config";
		reg = <0x12100200 0x10>;
	};
#endif

	vioc_disp: vioc_disp@12000000 {
		compatible = "telechips,vioc_disp";
		reg = <0x12000000 0x100 0x12000100 0x100 0x12000200 0x100>;
		interrupts = <GIC_SPI VIOC0_IRQI IRQ_TYPE_LEVEL_HIGH>, <GIC_SPI VIOC0_IRQI IRQ_TYPE_LEVEL_HIGH>, <GIC_SPI VIOC0_IRQI IRQ_TYPE_LEVEL_HIGH>;
		clocks = <&clk_ddi DDIBUS_VIOC>, <&clk_peri PERI_LCD0>, <&clk_peri PERI_LCD1>, <&clk_peri PERI_LCD2>;
		clock-names = "ddi-clk", "disp0-clk", "disp1-clk", "disp2-clk";
	};

	vioc_rdma: vioc_rdma@12000400{
		compatible = "telechips,vioc_rdma";
		reg = <0x12000400 0x100 0x12000500 0x100 0x12000600 0x100 0x12000700 0x100
				0x12000800 0x100 0x12000900 0x100 0x12000a00 0x100  0x12000b00 0x100
				0x12000c00 0x100 0x12000d00 0x100 0x12000e00 0x100  0x12000f00 0x100
				0x12001000 0x100 0x12001100 0x100 0x12001200 0x100  0x12001300 0x100
				0x12001400 0x100  0x12001500 0x100>;
		interrupts = <GIC_SPI VIOC0_IRQI IRQ_TYPE_LEVEL_HIGH>,
			     <GIC_SPI VIOC0_IRQI IRQ_TYPE_LEVEL_HIGH>,
			     <GIC_SPI VIOC0_IRQI IRQ_TYPE_LEVEL_HIGH>,
			     <GIC_SPI VIOC0_IRQI IRQ_TYPE_LEVEL_HIGH>,
			     <GIC_SPI VIOC0_IRQI IRQ_TYPE_LEVEL_HIGH>,
			     <GIC_SPI VIOC0_IRQI IRQ_TYPE_LEVEL_HIGH>,
			     <GIC_SPI VIOC0_IRQI IRQ_TYPE_LEVEL_HIGH>,
			     <GIC_SPI VIOC0_IRQI IRQ_TYPE_LEVEL_HIGH>,
			     <GIC_SPI VIOC0_IRQI IRQ_TYPE_LEVEL_HIGH>,
			     <GIC_SPI VIOC0_IRQI IRQ_TYPE_LEVEL_HIGH>,
			     <GIC_SPI VIOC0_IRQI IRQ_TYPE_LEVEL_HIGH>,
			     <GIC_SPI VIOC0_IRQI IRQ_TYPE_LEVEL_HIGH>,
			     <GIC_SPI VIOC0_IRQI IRQ_TYPE_LEVEL_HIGH>,
			     <GIC_SPI VIOC0_IRQI IRQ_TYPE_LEVEL_HIGH>,
			     <GIC_SPI VIOC0_IRQI IRQ_TYPE_LEVEL_HIGH>,
			     <GIC_SPI VIOC0_IRQI IRQ_TYPE_LEVEL_HIGH>,
			     <GIC_SPI VIOC0_IRQI IRQ_TYPE_LEVEL_HIGH>,
			     <GIC_SPI VIOC0_IRQI IRQ_TYPE_LEVEL_HIGH>;
	};

	vioc_wmix: vioc_wmix@12001800{
		compatible = "telechips,vioc_wmix";
		reg = <0x12001800 0x100 0x12001900 0x100 0x12001a00 0x100 0x12001b00 0x100
				0x12001c00 0x100 0x12001d00 0x100 0x12001e00 0x100>;
		interrupts = <GIC_SPI VIOC0_IRQI IRQ_TYPE_LEVEL_HIGH>,
			     <GIC_SPI VIOC0_IRQI IRQ_TYPE_LEVEL_HIGH>,
			     <GIC_SPI VIOC0_IRQI IRQ_TYPE_LEVEL_HIGH>,
			     <GIC_SPI VIOC0_IRQI IRQ_TYPE_LEVEL_HIGH>,
			     <GIC_SPI VIOC0_IRQI IRQ_TYPE_LEVEL_HIGH>,
			     <GIC_SPI VIOC0_IRQI IRQ_TYPE_LEVEL_HIGH>,
			     <GIC_SPI VIOC0_IRQI IRQ_TYPE_LEVEL_HIGH>;
	};

	vioc_scaler:vioc_scaler@12002000{
		compatible = "telechips,scaler";
		reg = <0x12002000 0x100 0x12002100 0x100 0x12002200 0x100>;
		status = "disabled";
	};

	vioc_wdma:vioc_wdma@12002800{
		compatible = "telechips,vioc_wdma";
		reg = <0x12002800 0x100 0x12002900 0x100 0x12002a00 0x100 0x12002b00 0x100
				0x12002c00 0x100 0x12002d00 0x100 0x12002e00 0x100  0x12002f00 0x100
				0x12003000 0x100 0x12014000 0x100 0x12014100 0x100 0x12014200 0x100
				0x12014300 0x100 0x12014400 0x100>;
		interrupts = <GIC_SPI VIOC0_IRQI IRQ_TYPE_LEVEL_HIGH>,
			     <GIC_SPI VIOC0_IRQI IRQ_TYPE_LEVEL_HIGH>,
			     <GIC_SPI VIOC0_IRQI IRQ_TYPE_LEVEL_HIGH>,
			     <GIC_SPI VIOC0_IRQI IRQ_TYPE_LEVEL_HIGH>,
			     <GIC_SPI VIOC0_IRQI IRQ_TYPE_LEVEL_HIGH>,
			     <GIC_SPI VIOC0_IRQI IRQ_TYPE_LEVEL_HIGH>,
			     <GIC_SPI VIOC0_IRQI IRQ_TYPE_LEVEL_HIGH>,
			     <GIC_SPI VIOC0_IRQI IRQ_TYPE_LEVEL_HIGH>,
			     <GIC_SPI VIOC0_IRQI IRQ_TYPE_LEVEL_HIGH>,
			     <GIC_SPI VIOC0_IRQI IRQ_TYPE_LEVEL_HIGH>,
			     <GIC_SPI VIOC0_IRQI IRQ_TYPE_LEVEL_HIGH>,
			     <GIC_SPI VIOC0_IRQI IRQ_TYPE_LEVEL_HIGH>,
			     <GIC_SPI VIOC0_IRQI IRQ_TYPE_LEVEL_HIGH>,
			     <GIC_SPI VIOC0_IRQI IRQ_TYPE_LEVEL_HIGH>;
	};

	vioc_vin:vioc_vin@12004000{
		compatible = "telechips,vioc_vin";
		reg = <	0x12004000 0x400 0x12004400 0x600
			0x12005000 0x400 0x12005400 0x600
			0x12006000 0x400 0x12006400 0x600
			0x12007000 0x400 0x12007400 0x600
			0x12018000 0x400 0x12018400 0x600
			0x12019000 0x400 0x12019400 0x600
			0x1201a000 0x400 0x1201a400 0x600
			0x1201b000 0x400 0x1201b400 0x600>;
		interrupts = <GIC_SPI VIOC0_IRQI IRQ_TYPE_LEVEL_HIGH>,
			     <GIC_SPI VIOC0_IRQI IRQ_TYPE_LEVEL_HIGH>,
			     <GIC_SPI VIOC0_IRQI IRQ_TYPE_LEVEL_HIGH>,
			     <GIC_SPI VIOC0_IRQI IRQ_TYPE_LEVEL_HIGH>,
			     <GIC_SPI VIOC0_IRQI IRQ_TYPE_LEVEL_HIGH>,
			     <GIC_SPI VIOC0_IRQI IRQ_TYPE_LEVEL_HIGH>,
			     <GIC_SPI VIOC0_IRQI IRQ_TYPE_LEVEL_HIGH>,
			     <GIC_SPI VIOC0_IRQI IRQ_TYPE_LEVEL_HIGH>,
			     <GIC_SPI VIOC0_IRQI IRQ_TYPE_LEVEL_HIGH>,
			     <GIC_SPI VIOC0_IRQI IRQ_TYPE_LEVEL_HIGH>,
			     <GIC_SPI VIOC0_IRQI IRQ_TYPE_LEVEL_HIGH>,
			     <GIC_SPI VIOC0_IRQI IRQ_TYPE_LEVEL_HIGH>,
			     <GIC_SPI VIOC0_IRQI IRQ_TYPE_LEVEL_HIGH>,
			     <GIC_SPI VIOC0_IRQI IRQ_TYPE_LEVEL_HIGH>,
			     <GIC_SPI VIOC0_IRQI IRQ_TYPE_LEVEL_HIGH>,
			     <GIC_SPI VIOC0_IRQI IRQ_TYPE_LEVEL_HIGH>;
	};

	vioc_viqe:vioc_viqe@1200d000{
		compatible = "telechips,vioc_viqe";
		reg = <0x1200d000 0x1000 0x12010000 0x1000>;
	};

	viqe_hidden:viqe_hidden{
		reg = <0x1200d100 0x4 0x1200d10c 0x4>;
	};

	vioc_deintls:vioc_deintls@12003800{
		compatible = "telechips,vioc_deintls";
		reg = <0x12003800 0x100>;
		status = "disabled";
	};

	vioc_fifo:vioc_fifo@12003b00{
		compatible = "telechips,vioc_fifo";
		reg = <0x12003b00 0x100>;
		status = "disabled";
	};

	vioc_rdma_arbitor:vioc_rdma_arbitor@12003f00{
		reg = <0x12003f00 0x20 0x12003f20 0x20 0x12003f40 0x20 0x12003f60 0x20>;
		arbitor_num = <4>;
	};

	mipi_csi2:mipi_csi@123c0000 {
		compatible = "telechips,mipi_csi2";
		reg = <0x1bc00800 0x120>,	/* csi0_base */
		      <0x1bc00a00 0x05c>,	/* gdb0_base */
		      <0x1bc00000 0x014>,	/* ckc_base */
		      <0x1bc00400 0x120>;	/* cfg_base */
		interrupts = <GIC_SPI 158 IRQ_TYPE_LEVEL_HIGH>,		// MIPI0 interrupt
			     <GIC_SPI 159 IRQ_TYPE_LEVEL_HIGH>;		// MIPI1 interrupt
	 };
/*
	mipi_generic_data_buffer:mipi_generic_data_buffer@123c0200 {
		compatible = "telechips,mipi_generic_data_buffer";
		reg = <0x123c0200 0x5c>;
		clocks = <&clk_peri PERI_MIPI_CSI>;
	};
*/

	fbdisplay: fbdisplay@12000000 {
		compatible = "telechips,vioc-fb";
		reg = <0x12000000 0x10000>;
		telechips,fbdisplay_num = <0>;
		telechips,rdma_arbitor=<&vioc_rdma_arbitor>;
		memory-region = <&pmap_fb_video>;

		fbdisplay0:fbdisplay0@12000000{
			telechips,disp = <&vioc_disp VIOC_DISP0>;
			telechips,wmixer = <&vioc_wmix VIOC_WMIX0>;
			telechips,rdma = <&vioc_rdma VIOC_RDMA00 VIOC_RDMA01 VIOC_RDMA02 VIOC_RDMA03>;
			telechips,wdma = <&vioc_wdma VIOC_WDMA00>;
		};
	};

/*
	gpu0: gpu@0x10200000 {
                compatible = "arm,mali-midgard";
		status = "okay";
                reg = <0x10200000 0x4000>;
                interrupts = <GIC_SPI 93 IRQ_TYPE_LEVEL_HIGH>,
                             <GIC_SPI 93 IRQ_TYPE_LEVEL_HIGH>,
                             <GIC_SPI 93 IRQ_TYPE_LEVEL_HIGH>;
                interrupt-names = "JOB", "MMU", "GPU";
                clocks = <&clk_fbus FBUS_GPU>;
                clock-names = "mali_clk";
        };
*/

	fb0 {
		compatible = "telechips,fb";
		status = "okay";
		memory-region = <&pmap_fb_video>;
		xres = <1920>;
		yres = <720>;
		bpp = <32>;
		mode = <FBX_TRIPLE>;
		update-type = <FBX_OVERLAY_UPDATE>;
		device-priority = <FBX_DEVICE_LVDS>;
		telechips,disp = <&vioc_disp VIOC_DISP0 VIOC_DISP1>;
		telechips,wmixer = <&vioc_wmix VIOC_WMIX0 VIOC_WMIX1>;
		telechips,rdma = <&vioc_rdma VIOC_RDMA01 VIOC_RDMA04>;

		//to use the option below, set CONFIG_FB_NEW_HALFDISPLAY_SUPPORT on menuconfig
		telechips,scaler = <&vioc_scaler VIOC_SCALER0>;
		fbx_region {
			x = <0>;
			y = <0>;
			width = <960>;
			height = <720>;
		};
	};

	#if defined(CONFIG_OVERLAY_DPGL)
	fb1 {
		compatible = "telechips,fb";
		status = "okay";
		memory-region = <&pmap_fb1_video>;
		xres = <1920>;
		yres = <720>;
		bpp = <32>;
		mode = <FBX_TRIPLE>;
		update-type = <FBX_NOWAIT_UPDATE>;
		device-priority = <FBX_DEVICE_NONE>;
		telechips,wdma = <&vioc_wdma  VIOC_WDMA05>;
		telechips,wmixer = <&vioc_wmix VIOC_WMIX5>;
		telechips,rdma = <&vioc_rdma VIOC_RDMA16>;

		clocks = <&clk_ddi DDIBUS_VIOC>;
		clock-names = "ddi-clk";
	};
	#endif

	tcc_overlay_drv {
		compatible = "telechips,tcc_overlay";
		fbdisplay-overlay = <&fbdisplay>;
		rdmas = <&vioc_rdma VIOC_RDMA00 VIOC_RDMA01 VIOC_RDMA02 VIOC_RDMA03 VIOC_RDMA04 VIOC_RDMA05 VIOC_RDMA06 VIOC_RDMA07>;
		wmixs = <&vioc_wmix VIOC_WMIX0 VIOC_WMIX1>;
		rdma_init_layer = <1>;
		status = "okay";
	};

/*
	tcc_overlay_drv1: tcc_overlay_drv@1 {
		compatible = "telechips,tcc_overlay";
		fbdisplay-overlay = <1>;
		rdmas = <&vioc_rdma VIOC_RDMA00 VIOC_RDMA01 VIOC_RDMA02 VIOC_RDMA03 VIOC_RDMA04 VIOC_RDMA05 VIOC_RDMA06 VIOC_RDMA07>;
		wmixs = <&vioc_wmix VIOC_WMIX0 VIOC_WMIX1>;
		status = "okay";
	};
*/

	wmixer_drv1: wmixer_drv@1 {
		compatible = "telechips,wmixer_drv";
		reg = <0x1 0x0>;	/* Dummy regs. */
		clocks = <&clk_ddi DDIBUS_VIOC>;
		rdmas = <&vioc_rdma VIOC_RDMA12 VIOC_RDMA13>;
		scalers = <&vioc_scaler VIOC_SCALER0>;	/* id:0, path:15 */
		wmixs = <&vioc_wmix VIOC_WMIX3>;	/* id:3, path:- TODO: WMIX_MAX occurs error*/
		wdmas = <&vioc_wdma VIOC_WDMA03>;
		status = "okay";
	};

	switch_reverse {
		compatible = "telechips,switch_reverse";
		status = "okay";

		pinctrl-names = "default";
		pinctrl-0 = <&switch_reverse_ma15>;

		switch-gpios = <&gpma 15 1>;
		switch-active = <0>;
	};

	videoinput0: videoinput@0 {
		compatible	= "telechips,video-input";
		clocks		= <&clk_ddi DDIBUS_VIOC>;
		rdma		= <&vioc_rdma		VIOC_RDMA16>;
		vin		= <&vioc_vin		VIOC_VIN00>;
		viqe		= <&vioc_viqe		VIOC_VIQE1>;
		viqe_set	= <&viqe_hidden>;
		deintls		= <&vioc_deintls	VIOC_DEINTLS0>;
		scaler		= <&vioc_scaler		VIOC_SCALER2>;
		wmixer		= <&vioc_wmix		VIOC_WMIX5>;
		wdma		= <&vioc_wdma		VIOC_WDMA05>;
		fifo		= <&vioc_fifo		VIOC_FIFO0>;
		status		= "okay";
	};

	videoinput1: videoinput@1 {
		compatible	= "telechips,video-input";
		clocks		= <&clk_ddi DDIBUS_VIOC>;
		rdma		= <&vioc_rdma		VIOC_RDMA17>;
		vin		= <&vioc_vin		VIOC_VIN10>;
		viqe		= <&vioc_viqe		VIOC_VIQE1>;
		viqe_set	= <&viqe_hidden>;
		deintls		= <&vioc_deintls	VIOC_DEINTLS0>;
		scaler		= <&vioc_scaler		VIOC_SCALER2>;
		wmixer		= <&vioc_wmix		VIOC_WMIX6>;
		wdma		= <&vioc_wdma		VIOC_WDMA07>;
		fifo		= <&vioc_fifo		VIOC_FIFO0>;
		status		= "okay";
	};

	videoinput2: videoinput@2 {
		compatible	= "telechips,video-input";
		clocks		= <&clk_ddi DDIBUS_VIOC>;
		rdma		= <&vioc_rdma		VIOC_RDMA13>;
		vin		= <&vioc_vin		VIOC_VIN20>;
		viqe		= <&vioc_viqe		VIOC_VIQE1>;
		viqe_set	= <&viqe_hidden>;
		deintls		= <&vioc_deintls	VIOC_DEINTLS0>;
		scaler		= <&vioc_scaler		VIOC_SCALER2>;
		wmixer		= <&vioc_wmix		VIOC_WMIX3>;
		wdma		= <&vioc_wdma		VIOC_WDMA03>;
		fifo		= <&vioc_fifo		VIOC_FIFO0>;
		status		= "okay";
	};

	videoinput3: videoinput@3 {
		compatible	= "telechips,video-input";
		clocks		= <&clk_ddi DDIBUS_VIOC>;
		rdma		= <&vioc_rdma		VIOC_RDMA15>;
		vin		= <&vioc_vin		VIOC_VIN30>;
		viqe		= <&vioc_viqe		VIOC_VIQE1>;
		viqe_set	= <&viqe_hidden>;
		deintls		= <&vioc_deintls	VIOC_DEINTLS0>;
		scaler		= <&vioc_scaler		VIOC_SCALER2>;
		wmixer		= <&vioc_wmix		VIOC_WMIX4>;
		wdma		= <&vioc_wdma		VIOC_WDMA04>;
		fifo		= <&vioc_fifo		VIOC_FIFO0>;
		status		= "okay";
	};

	videoinput4: videoinput@4 {
		compatible	= "telechips,video-input";
		clocks		= <&clk_ddi DDIBUS_VIOC>;
		vin		= <&vioc_vin		VIOC_VIN40>;
		wdma		= <&vioc_wdma		VIOC_WDMA09>;
		fifo		= <&vioc_fifo		VIOC_FIFO0>;
		status		= "okay";
	};

	videoinput5: videoinput@5 {
		compatible	= "telechips,video-input";
		clocks		= <&clk_ddi DDIBUS_VIOC>;
		vin		= <&vioc_vin		VIOC_VIN50>;
		wdma		= <&vioc_wdma		VIOC_WDMA10>;
		fifo		= <&vioc_fifo		VIOC_FIFO0>;
		status		= "okay";
	};

	videoinput6: videoinput@6 {
		compatible	= "telechips,video-input";
		clocks		= <&clk_ddi DDIBUS_VIOC>;
		vin		= <&vioc_vin		VIOC_VIN60>;
		wdma		= <&vioc_wdma		VIOC_WDMA11>;
		fifo		= <&vioc_fifo		VIOC_FIFO0>;
		status		= "okay";
	};

	videoinput7: videoinput@7 {
		compatible	= "telechips,video-input";
		clocks		= <&clk_ddi DDIBUS_VIOC>;
		vin		= <&vioc_vin		VIOC_VIN70>;
		wdma		= <&vioc_wdma		VIOC_WDMA12>;
		fifo		= <&vioc_fifo		VIOC_FIFO0>;
		status		= "okay";
	};

	/* A53 <-> R5 */
	micom_mbox: mbox@0x1BA30000 {
		compatible = "telechips,multichannel-mailbox";
		reg = <0x1BA30000 0x100>;
		interrupts = <GIC_SPI 444 IRQ_TYPE_LEVEL_HIGH>,
				   <GIC_SPI 445 IRQ_TYPE_LEVEL_HIGH>;
		#mbox-cells = <1>;
		max-channel = <TCC_MICOM_MBOX1_MAX>;
	};

	/* A53 <-> A72 */
	cb_mbox: mbox@0x17B00000 {
		compatible = "telechips,multichannel-mailbox";
		reg = <0x17B00000 0x100>;
		interrupts = <GIC_SPI 365 IRQ_TYPE_LEVEL_HIGH>,
				   <GIC_SPI 366 IRQ_TYPE_LEVEL_HIGH>;
		#mbox-cells = <1>;
		max-channel = <TCC_CB_MBOX_MAX>;
	};

	/* micom_mbox test */
	mbox_test0: mbox_test@0 {
		 compatible = "telechips,mbox_test";
		 device-name = "micom_mbox_test";
		 mbox-names ="mbox_test";
		 mboxes = <&micom_mbox TCC_MICOM_MBOX0_TEST>;
		 mbox-id = TCC_MBOX_TEST_ID;
	 };

	/* cb_mbox test */
	mbox_test1: mbox_test@1 {
		 compatible = "telechips,mbox_test";
		 device-name = "cb_mbox_test";
		 mbox-names ="mbox_test";
		 mboxes = <&cb_mbox TCC_CB_MBOX_TEST>;
		 mbox-id = TCC_MBOX_TEST_ID;
	 };

	/* ipc for r5(micom) */
	ipc0: tcc_ipc@0 {
		 compatible = "telechips,tcc_ipc";
		 device-name = "tcc_ipc_micom";
		 mbox-names ="micom-ipc";
		 mboxes = <&micom_mbox TCC_MICOM_MBOX0_IPC>;
		 mbox-id = TCC_MBOX_IPC_ID;
	 };

	/* ipc for A72 */
	ipc1: tcc_ipc@1 {
		 compatible = "telechips,tcc_ipc";
		 device-name = "tcc_ipc_ap";
		 mbox-names ="ap-ipc";
		 mboxes = <&cb_mbox TCC_CB_MBOX_IPC>;
		 mbox-id = TCC_MBOX_IPC_ID;
	 };
};

&pinctrl {
	gpa: gpa {
		gpio-controller;
		#gpio-cells = <2>;
		reg = <0x0 0 32>;
	};

	gpb: gpb {
		gpio-controller;
		#gpio-cells = <2>;
		reg = <0x40 0 29>;
	};

	gpc: gpc {
		gpio-controller;
		#gpio-cells = <2>;
		reg = <0x80 0 30>;
	};

	gpe: gpe {
		gpio-controller;
		#gpio-cells = <2>;
		reg = <0x100 0 20>;
	};

	gpg: gpg {
		gpio-controller;
		#gpio-cells = <2>;
		reg = <0x180 0 11>;
	};

	gph: gph {
		gpio-controller;
		#gpio-cells = <2>;
		reg = <0x640 0 12>;
	};

	gpk: gpk {
		gpio-controller;
		#gpio-cells = <2>;
		reg = <0x800 0 19>;
	};

	gpma: gpma {
		gpio-controller;
		#gpio-cells = <2>;
		reg = <0x6C0 0 30>;
	};

	gpmb: gpmb {
		gpio-controller;
		#gpio-cells = <2>;
		reg = <0x700 0 32>;
	};

	gpmc: gpmc {
		gpio-controller;
		#gpio-cells = <2>;
		reg = <0x740 0 30>;
	};

	gpmd: gpmd {
		gpio-controller;
		#gpio-cells = <2>;
		reg = <0x780 0 16>;
	};

	gpsd0: gpsd0 {
		gpio-controller;
		#gpio-cells = <2>;
		reg = <0x200 0 15>;
	};

	gpsd1: gpsd1 {
		gpio-controller;
		#gpio-cells = <2>;
		reg = <0x240 0 11>;
	};

	gpsd2: gpsd2 {
		gpio-controller;
		#gpio-cells = <2>;
		reg = <0x600 0 10>;
	};

	uart28_data: uart28_data {
		telechips,pins = "gph-4", "gph-5";
		telechips,pin-function = <7>;
	};

	switch_reverse_ma15: switch_reverse_ma15 {
		telechips,pins = "gpma-15";
		telechips,pin-function = <0>;
		telechips,input-enable;
		telechips,no-pull;
	};

	cam0_8bit_idle: cam0_8bit_idle {
		telechips,pins = "gpa-0",  "gpa-1",  "gpa-2",  "gpa-11",  "gpa-12",
				 "gpa-3",  "gpa-4",  "gpa-5",  "gpa-6",  "gpa-7",  "gpa-8",  "gpa-9",  "gpa-10";
		telechips,pin-function = <0>;
		telechips,output-low;
	};

	cam0_16bit_idle: cam0_16bit_idle {
		telechips,pins = "gpa-0",
				 "gpa-3",  "gpa-4",  "gpa-5",  "gpa-6",  "gpa-7",  "gpa-8",  "gpa-9",  "gpa-10",
				 "gpa-13", "gpa-14", "gpa-15", "gpa-16", "gpa-17", "gpa-18", "gpa-19", "gpa-20";
		telechips,pin-function = <0>;
		telechips,output-low;
	};

	cam0_clk: cam0_clk {
		telechips,pins = "gpa-0";
		telechips,pin-function = <3>;
		telechips,drive-strength = <3>;
	};

	cam0_hsync: cam0_hsync {
		telechips,pins = "gpa-1";
		telechips,pin-function = <3>;
		telechips,drive-strength = <3>;
	};

	cam0_vsync: cam0_vsync {
		telechips,pins = "gpa-2";
		telechips,pin-function = <3>;
		telechips,drive-strength = <3>;
	};

	cam0_fld: cam0_fld {
		telechips,pins = "gpa-11";
		telechips,pin-function = <3>;
		telechips,drive-strength = <3>;
	};

	cam0_de: cam0_de {
		telechips,pins = "gpa-12";
		telechips,pin-function = <3>;
		telechips,drive-strength = <3>;
	};

	cam0_data_8bit: cam0_data_8bit {
		telechips,pins = "gpa-3",  "gpa-4",  "gpa-5",  "gpa-6",  "gpa-7",  "gpa-8",  "gpa-9",  "gpa-10";
		telechips,pin-function = <3>;
		telechips,drive-strength = <3>;
	};

	cam0_data_16bit: cam0_data_16bit {
		telechips,pins = "gpa-3",  "gpa-4",  "gpa-5",  "gpa-6",  "gpa-7",  "gpa-8",  "gpa-9",  "gpa-10",
				 "gpa-13", "gpa-14", "gpa-15", "gpa-16", "gpa-17", "gpa-18", "gpa-19", "gpa-20";
		telechips,pin-function = <3>;
		telechips,drive-strength = <3>;
	};
};

&uart0 {
	pinctrl-names = "default";
	pinctrl-0 = <&uart28_data>;
	status = "okay";
};
